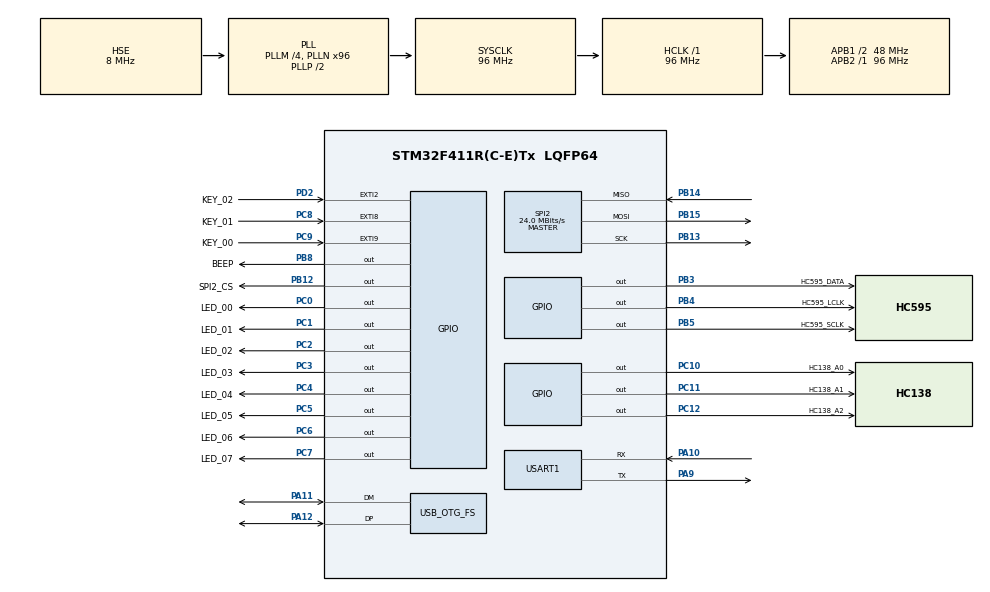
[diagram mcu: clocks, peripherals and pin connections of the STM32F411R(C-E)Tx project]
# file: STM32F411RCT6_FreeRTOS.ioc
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FREERTOS.MEMORY_ALLOCATION=2
FREERTOS.Tasks01=defaultTask,0,128,StartDefaultTask,Default,NULL,Dynamic,NULL,NULL;LED,0,128,Start_LED,Default,NULL,Dynamic,NULL,NULL;SEG,2,128,Start_SEG,Default,NULL,Dynamic,NULL,NULL;TEST,0,128,Start_TEST,Default,NULL,Dynamic,NULL,NULL
FREERTOS.configENABLE_FPU=1
Mcu.Family=STM32F4
Mcu.Name=STM32F411R(C-E)Tx
Mcu.Package=LQFP64
NVIC.EXTI2_IRQn=true\:5\:0\:false\:false\:true\:true\:true\:true\:true
NVIC.EXTI9_5_IRQn=true\:5\:0\:false\:false\:true\:true\:true\:true\:true
NVIC.PriorityGroup=NVIC_PRIORITYGROUP_4
NVIC.TIM1_TRG_COM_TIM11_IRQn=true\:15\:0\:false\:false\:true\:false\:false\:true\:true
NVIC.TimeBase=TIM1_TRG_COM_TIM11_IRQn
NVIC.TimeBaseIP=TIM11
PA10.Mode=Asynchronous
PA10.Signal=USART1_RX
PA11.Mode=Device_Only
PA11.Signal=USB_OTG_FS_DM
PA12.Mode=Device_Only
PA12.Signal=USB_OTG_FS_DP
PA13.Mode=Serial_Wire
PA13.Signal=SYS_JTMS-SWDIO
PA14.Mode=Serial_Wire
PA14.Signal=SYS_JTCK-SWCLK
PA9.Mode=Asynchronous
PA9.Signal=USART1_TX
PB12.GPIO_Label=SPI2_CS
PB12.GPIO_PuPd=GPIO_PULLUP
PB12.GPIO_Speed=GPIO_SPEED_FREQ_VERY_HIGH
PB12.PinState=GPIO_PIN_SET
PB12.Signal=GPIO_Output
PB13.Mode=Full_Duplex_Master
PB13.Signal=SPI2_SCK
PB14.Mode=Full_Duplex_Master
PB14.Signal=SPI2_MISO
PB15.Mode=Full_Duplex_Master
PB15.Signal=SPI2_MOSI
PB3.GPIO_Label=HC595_DATA
PB3.GPIO_PuPd=GPIO_PULLDOWN
PB3.GPIO_Speed=GPIO_SPEED_FREQ_VERY_HIGH
PB3.PinState=GPIO_PIN_RESET
PB3.Signal=GPIO_Output
PB4.GPIO_Label=HC595_LCLK
PB4.GPIO_PuPd=GPIO_PULLDOWN
PB4.GPIO_Speed=GPIO_SPEED_FREQ_VERY_HIGH
PB4.PinState=GPIO_PIN_RESET
PB4.Signal=GPIO_Output
PB5.GPIO_Label=HC595_SCLK
PB5.GPIO_PuPd=GPIO_PULLDOWN
PB5.GPIO_Speed=GPIO_SPEED_FREQ_VERY_HIGH
PB5.PinState=GPIO_PIN_RESET
PB5.Signal=GPIO_Output
PB8.GPIO_Label=BEEP
PB8.GPIO_PuPd=GPIO_PULLUP
PB8.PinState=GPIO_PIN_SET
PB8.Signal=GPIO_Output
PC0.GPIO_Label=LED_00
PC0.GPIO_PuPd=GPIO_PULLUP
PC0.PinState=GPIO_PIN_SET
PC0.Signal=GPIO_Output
PC1.GPIO_Label=LED_01
PC1.GPIO_PuPd=GPIO_PULLUP
PC1.PinState=GPIO_PIN_SET
PC1.Signal=GPIO_Output
PC10.GPIO_Label=HC138_A0
PC10.GPIO_PuPd=GPIO_PULLUP
PC10.GPIO_Speed=GPIO_SPEED_FREQ_VERY_HIGH
PC10.PinState=GPIO_PIN_SET
PC10.Signal=GPIO_Output
PC11.GPIO_Label=HC138_A1
PC11.GPIO_PuPd=GPIO_PULLUP
PC11.GPIO_Speed=GPIO_SPEED_FREQ_VERY_HIGH
PC11.PinState=GPIO_PIN_SET
PC11.Signal=GPIO_Output
PC12.GPIO_Label=HC138_A2
PC12.GPIO_PuPd=GPIO_PULLUP
PC12.GPIO_Speed=GPIO_SPEED_FREQ_VERY_HIGH
PC12.PinState=GPIO_PIN_SET
PC12.Signal=GPIO_Output
PC14-OSC32_IN.Mode=LSE-External-Oscillator
PC14-OSC32_IN.Signal=RCC_OSC32_IN
PC15-OSC32_OUT.Mode=LSE-External-Oscillator
PC15-OSC32_OUT.Signal=RCC_OSC32_OUT
PC2.GPIO_Label=LED_02
PC2.GPIO_PuPd=GPIO_PULLUP
PC2.PinState=GPIO_PIN_SET
PC2.Signal=GPIO_Output
PC3.GPIO_Label=LED_03
PC3.GPIO_PuPd=GPIO_PULLUP
PC3.PinState=GPIO_PIN_SET
PC3.Signal=GPIO_Output
PC4.GPIO_Label=LED_04
PC4.GPIO_PuPd=GPIO_PULLUP
PC4.PinState=GPIO_PIN_SET
PC4.Signal=GPIO_Output
PC5.GPIO_Label=LED_05
PC5.GPIO_PuPd=GPIO_PULLUP
PC5.PinState=GPIO_PIN_SET
PC5.Signal=GPIO_Output
PC6.GPIO_Label=LED_06
PC6.GPIO_PuPd=GPIO_PULLUP
PC6.PinState=GPIO_PIN_SET
PC6.Signal=GPIO_Output
PC7.GPIO_Label=LED_07
PC7.GPIO_PuPd=GPIO_PULLUP
PC7.PinState=GPIO_PIN_SET
PC7.Signal=GPIO_Output
PC8.GPIO_Label=KEY_01
PC8.GPIO_ModeDefaultEXTI=GPIO_MODE_IT_FALLING
PC8.GPIO_PuPd=GPIO_PULLUP
PC8.Signal=GPXTI8
PC9.GPIO_Label=KEY_00
PC9.GPIO_ModeDefaultEXTI=GPIO_MODE_IT_FALLING
PC9.GPIO_PuPd=GPIO_PULLUP
PC9.Signal=GPXTI9
PD2.GPIO_Label=KEY_02
PD2.GPIO_ModeDefaultEXTI=GPIO_MODE_IT_FALLING
PD2.GPIO_PuPd=GPIO_PULLUP
PD2.Signal=GPXTI2
PH0\ -\ OSC_IN.Mode=HSE-External-Oscillator
PH0\ -\ OSC_IN.Signal=RCC_OSC_IN
PH1\ -\ OSC_OUT.Mode=HSE-External-Oscillator
PH1\ -\ OSC_OUT.Signal=RCC_OSC_OUT
ProjectManager.HeapSize=0x200
ProjectManager.StackSize=0x400
ProjectManager.TargetToolchain=MDK-ARM V5.32
RCC.48MHZClocksFreq_Value=48000000
RCC.AHBFreq_Value=96000000
RCC.APB1CLKDivider=RCC_HCLK_DIV2
RCC.APB1Freq_Value=48000000
RCC.APB1TimFreq_Value=96000000
RCC.APB2Freq_Value=96000000
RCC.APB2TimFreq_Value=96000000
RCC.CortexFreq_Value=96000000
RCC.HCLKFreq_Value=96000000
RCC.HSE_VALUE=8000000
RCC.HSI_VALUE=16000000
RCC.PLLI2SR=6
RCC.PLLM=4
RCC.PLLN=96
RCC.RCC_RTC_Clock_Source=RCC_RTCCLKSOURCE_LSE
RCC.RCC_RTC_Clock_SourceVirtual=RCC_RTCCLKSOURCE_LSE
RCC.SYSCLKFreq_VALUE=96000000
RCC.SYSCLKSource=RCC_SYSCLKSOURCE_PLLCLK
RCC.VCOOutputFreq_Value=192000000
RTC.Format=RTC_FORMAT_BIN
SPI2.BaudRatePrescaler=SPI_BAUDRATEPRESCALER_2
SPI2.CLKPhase=SPI_PHASE_2EDGE
SPI2.CLKPolarity=SPI_POLARITY_HIGH
SPI2.CalculateBaudRate=24.0 MBits/s
SPI2.Direction=SPI_DIRECTION_2LINES
SPI2.FirstBit=SPI_FIRSTBIT_MSB
SPI2.Mode=SPI_MODE_MASTER
SPI2.VirtualType=VM_MASTER
TIM10.AutoReloadPreload=TIM_AUTORELOAD_PRELOAD_DISABLE
TIM10.Period=65535
TIM10.Prescaler=95
USART1.OverSampling=UART_OVERSAMPLING_16
USART1.VirtualMode=VM_ASYNC
USB_OTG_FS.VirtualMode=Device_Only
VP_FREERTOS_VS_CMSIS_V1.Mode=CMSIS_V1
VP_RTC_VS_RTC_Activate.Mode=RTC_Enabled
VP_RTC_VS_RTC_Calendar.Mode=RTC_Calendar
VP_SYS_VS_tim11.Mode=TIM11
VP_TIM10_VS_ClockSourceINT.Mode=Enable_Timer
board=custom

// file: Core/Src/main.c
/* USER CODE BEGIN Header */
/**
  ******************************************************************************
  * @file           : main.c
  * @brief          : Main program body
  ******************************************************************************
  * @attention
  *
  * Copyright (c) 2022 STMicroelectronics.
  * All rights reserved.
  *
  * This software is licensed under terms that can be found in the LICENSE file
  * in the root directory of this software component.
  * If no LICENSE file comes with this software, it is provided AS-IS.
  *
  ******************************************************************************
  */
/* USER CODE END Header */
#include "main.h"
#include "cmsis_os.h"
#include "rtc.h"
#include "spi.h"
#include "tim.h"
#include "usart.h"
#include "usb_otg.h"
#include "gpio.h"

void SystemClock_Config(void);
void MX_FREERTOS_Init(void);

int main(void)
{

  /* MCU Configuration--------------------------------------------------------*/

  /* Reset of all peripherals, Initializes the Flash interface and the Systick. */
  HAL_Init();

  /* Configure the system clock */
  SystemClock_Config();

  /* Initialize all configured peripherals */
  MX_GPIO_Init();
  MX_RTC_Init();
  MX_USART1_UART_Init();
  MX_SPI2_Init();
  MX_USB_OTG_FS_PCD_Init();
  MX_TIM10_Init();

  /* Call init function for freertos objects (in freertos.c) */
  MX_FREERTOS_Init();

  /* Start scheduler */
  osKernelStart();

  /* We should never get here as control is now taken by the scheduler */
  /* Infinite loop */
  /* USER CODE BEGIN WHILE */
  while (1)
  {
    printf("Hanris\r\n");
    HAL_Delay(1000);
    /* USER CODE END WHILE */

  }
}

void SystemClock_Config(void)
{
  RCC_OscInitTypeDef RCC_OscInitStruct = {0};
  RCC_ClkInitTypeDef RCC_ClkInitStruct = {0};

  /** Configure the main internal regulator output voltage
  */
  __HAL_RCC_PWR_CLK_ENABLE();
  __HAL_PWR_VOLTAGESCALING_CONFIG(PWR_REGULATOR_VOLTAGE_SCALE1);

  /** Initializes the RCC Oscillators according to the specified parameters
  * in the RCC_OscInitTypeDef structure.
  */
  RCC_OscInitStruct.OscillatorType = RCC_OSCILLATORTYPE_HSE|RCC_OSCILLATORTYPE_LSE;
  RCC_OscInitStruct.HSEState = RCC_HSE_ON;
  RCC_OscInitStruct.LSEState = RCC_LSE_ON;
  RCC_OscInitStruct.PLL.PLLState = RCC_PLL_ON;
  RCC_OscInitStruct.PLL.PLLSource = RCC_PLLSOURCE_HSE;
  RCC_OscInitStruct.PLL.PLLM = 4;
  RCC_OscInitStruct.PLL.PLLN = 96;
  RCC_OscInitStruct.PLL.PLLP = RCC_PLLP_DIV2;
  RCC_OscInitStruct.PLL.PLLQ = 4;
  if (HAL_RCC_OscConfig(&RCC_OscInitStruct) != HAL_OK)
  {
    Error_Handler();
  }

  /** Initializes the CPU, AHB and APB buses clocks
  */
  RCC_ClkInitStruct.ClockType = RCC_CLOCKTYPE_HCLK|RCC_CLOCKTYPE_SYSCLK
                              |RCC_CLOCKTYPE_PCLK1|RCC_CLOCKTYPE_PCLK2;
  RCC_ClkInitStruct.SYSCLKSource = RCC_SYSCLKSOURCE_PLLCLK;
  RCC_ClkInitStruct.AHBCLKDivider = RCC_SYSCLK_DIV1;
  RCC_ClkInitStruct.APB1CLKDivider = RCC_HCLK_DIV2;
  RCC_ClkInitStruct.APB2CLKDivider = RCC_HCLK_DIV1;

  if (HAL_RCC_ClockConfig(&RCC_ClkInitStruct, FLASH_LATENCY_3) != HAL_OK)
  {
    Error_Handler();
  }
}

void HAL_TIM_PeriodElapsedCallback(TIM_HandleTypeDef *htim)
{
  if (htim->Instance == TIM11) {
    HAL_IncTick();
  }
}

void Error_Handler(void)
{
  __disable_irq();
  while (1)
  {
  }
}

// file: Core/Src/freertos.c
/* USER CODE BEGIN Header */
/**
  ******************************************************************************
  * File Name          : freertos.c
  * Description        : Code for freertos applications
  ******************************************************************************
  * @attention
  *
  * Copyright (c) 2022 STMicroelectronics.
  * All rights reserved.
  *
  * This software is licensed under terms that can be found in the LICENSE file
  * in the root directory of this software component.
  * If no LICENSE file comes with this software, it is provided AS-IS.
  *
  ******************************************************************************
  */
/* USER CODE END Header */

#include "FreeRTOS.h"
#include "task.h"
#include "main.h"
#include "cmsis_os.h"

osThreadId defaultTaskHandle;
osThreadId LEDHandle;
osThreadId SEGHandle;
osThreadId TESTHandle;

void StartDefaultTask(void const * argument);
void Start_LED(void const * argument);
void Start_SEG(void const * argument);
void Start_TEST(void const * argument);

void MX_FREERTOS_Init(void); /* (MISRA C 2004 rule 8.1) */

/* GetIdleTaskMemory prototype (linked to static allocation support) */
void vApplicationGetIdleTaskMemory( StaticTask_t **ppxIdleTaskTCBBuffer, StackType_t **ppxIdleTaskStackBuffer, uint32_t *pulIdleTaskStackSize );

/* USER CODE BEGIN GET_IDLE_TASK_MEMORY */
static StaticTask_t xIdleTaskTCBBuffer;
static StackType_t xIdleStack[configMINIMAL_STACK_SIZE];

void vApplicationGetIdleTaskMemory( StaticTask_t **ppxIdleTaskTCBBuffer, StackType_t **ppxIdleTaskStackBuffer, uint32_t *pulIdleTaskStackSize )
{
  *ppxIdleTaskTCBBuffer = &xIdleTaskTCBBuffer;
  *ppxIdleTaskStackBuffer = &xIdleStack[0];
  *pulIdleTaskStackSize = configMINIMAL_STACK_SIZE;
  /* place for user code */
}
/* USER CODE END GET_IDLE_TASK_MEMORY */

void MX_FREERTOS_Init(void) {

  /* Create the thread(s) */
  /* definition and creation of defaultTask */
  osThreadDef(defaultTask, StartDefaultTask, osPriorityNormal, 0, 128);
  defaultTaskHandle = osThreadCreate(osThread(defaultTask), NULL);

  /* definition and creation of LED */
  osThreadDef(LED, Start_LED, osPriorityNormal, 0, 128);
  LEDHandle = osThreadCreate(osThread(LED), NULL);

  /* definition and creation of SEG */
  osThreadDef(SEG, Start_SEG, osPriorityHigh, 0, 128);
  SEGHandle = osThreadCreate(osThread(SEG), NULL);

  /* definition and creation of TEST */
  osThreadDef(TEST, Start_TEST, osPriorityNormal, 0, 128);
  TESTHandle = osThreadCreate(osThread(TEST), NULL);

}

void StartDefaultTask(void const * argument)
{
  for(;;)
  {
    osDelay(1);
  }
}

void Start_LED(void const * argument)
{
  /* USER CODE BEGIN Start_LED */
  uint16_t Delay_Time = 350;
  int8_t nCount = 1;
  /* Infinite loop */
  for(;;)
  {
    for(nCount=1; nCount<9; nCount++)
    {
      F411_LED_Single(nCount, ON);
      osDelay(Delay_Time);
    }
    for(nCount=1; nCount<9; nCount++)
    {
      F411_LED_Single(nCount, OFF);
      osDelay(Delay_Time);
    }
  }
  /* USER CODE END Start_LED */
}

void Start_SEG(void const * argument)
{
  /* USER CODE BEGIN Start_SEG */
  F411_SEG(66666666, Point_Position_None);
  /* Infinite loop */
  for(;;)
  {
    F411_SEG_Run(LOW);
  }
  /* USER CODE END Start_SEG */
}

void Start_TEST(void const * argument)
{
  /* USER CODE BEGIN Start_TEST */
  //F411_Test();
  /* Infinite loop */
  for(;;)
  {
    osDelay(1);
  }
  /* USER CODE END Start_TEST */
}
